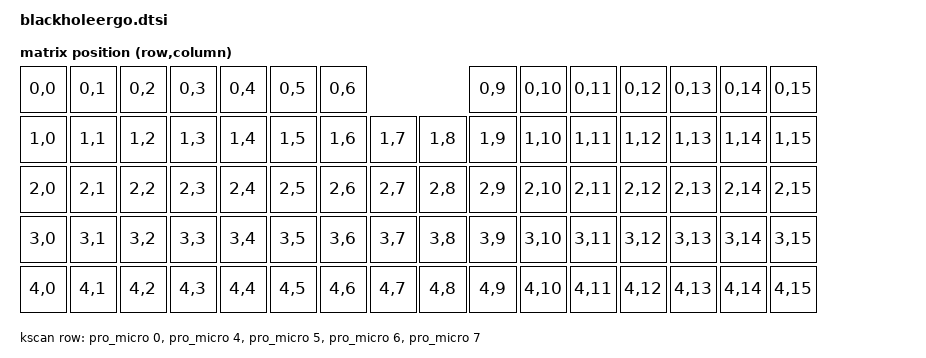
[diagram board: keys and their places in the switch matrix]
// This file was generated from a template. Edit it to match your keyboard.
// See https://zmk.dev/docs/development/hardware-integration/new-shield for more
// instructions.

#include <dt-bindings/zmk/matrix_transform.h>

#include "blackholeergo-layouts.dtsi"

/ {
    chosen {
        zmk,physical-layout = &default_layout;
        zephyr,display = &oled;
        
    };

    kscan: kscan {
        // If the hardware does not use a switch matrix, change this to the
        // appropriate driver and update the properties below to match.
        // See https://zmk.dev/docs/config/kscan for supported key scan drivers.
        compatible = "zmk,kscan-gpio-matrix";
        // Set this to "col2row" or "row2col" to match the hardware. If using
        // "row2col", change the col-gpios in the _left.overlay and _right.overlay
        // files to (GPIO_ACTIVE_HIGH | GPIO_PULL_DOWN) and the row-gpios here to
        // GPIO_ACTIVE_HIGH.
        diode-direction = "col2row";
        wakeup-source;

        // Replace these comments with the GPIO pins in the matrix.
        // See https://zmk.dev/docs/development/hardware-integration/new-shield#shield-overlays
        row-gpios
            = <&pro_micro 0 (GPIO_ACTIVE_HIGH | GPIO_PULL_DOWN)>
            , <&pro_micro 4 (GPIO_ACTIVE_HIGH | GPIO_PULL_DOWN)>
            , <&pro_micro 5 (GPIO_ACTIVE_HIGH | GPIO_PULL_DOWN)>
            , <&pro_micro 6 (GPIO_ACTIVE_HIGH | GPIO_PULL_DOWN)>
            , <&pro_micro 7 (GPIO_ACTIVE_HIGH | GPIO_PULL_DOWN)>
            ;
    };

    default_transform: default_transform {
        // See https://zmk.dev/docs/development/hardware-integration/new-shield#matrix-transform
        // for how to configure this
        compatible = "zmk,matrix-transform";
        columns = <16>;
        rows = <5>;

// | SW04 | SW10 | SW15 | SW20 | SW25 | SW29 | SW30 |             | SW30 | SW29 | SW25 | SW20 | SW15 | SW10 | SW04 |
// | SW03 | SW09 | SW14 | SW19 | SW24 | SW28 | SW34 | ES01   ES02 | SW34 | SW28 | SW24 | SW10 | SW14 | SW09 | SW03 |
// | SW02 | SW08 | SW13 | SW18 | SW23 | SW27 | SW35 | SW33 | SW33 | SW35 | SW27 | SW23 | SW18 | SW13 | SW08 | SW02 |
// | SW01 | SW07 | SW12 | SW17 | SW22 | SW26 |      |      |      |      | SW26 | SW22 | SW17 | SW12 | SW07 | SW01 |
// | SW06 | SW06 | SW11 | SW16 | SW21 |      |      | ---- | ---- |      |      | SW21 | SW16 | SW11 | SW06 | SW06 |
//                                    |      | SW38 |             | SW38 |      |
//                                    | SW36 | SW37 | SW32 | SW32 | SW37 | SW36 |
//                                                  | SW31 | SW31 |
        map = <
RC(0,0) RC(0,1) RC(0,2) RC(0,3) RC(0,4) RC(0,5) RC(0,6)                     RC(0,9) RC(0,10) RC(0,11)  RC(0,12) RC(0,13) RC(0,14) RC(0,15)
RC(1,0) RC(1,1) RC(1,2) RC(1,3) RC(1,4) RC(1,5) RC(1,6) RC(1,7)     RC(1,8) RC(1,9) RC(1,10) RC(1,11)  RC(1,12) RC(1,13) RC(1,14) RC(1,15)
RC(2,0) RC(2,1) RC(2,2) RC(2,3) RC(2,4) RC(2,5) RC(2,6) RC(2,7)     RC(2,8) RC(2,9) RC(2,10) RC(2,11)  RC(2,12) RC(2,13) RC(2,14) RC(2,15)
RC(3,0) RC(3,1) RC(3,2) RC(3,3) RC(3,4) RC(3,5) RC(3,6) RC(3,7)     RC(3,8) RC(3,9) RC(3,10) RC(3,11)  RC(3,12) RC(3,13) RC(3,14) RC(3,15)
RC(4,0) RC(4,1) RC(4,2) RC(4,3) RC(4,4) RC(4,5) RC(4,6) RC(4,7)     RC(4,8) RC(4,9) RC(4,10) RC(4,11)  RC(4,12) RC(4,13) RC(4,14) RC(4,15)
        >;
    };

    left_encoder: left_encoder {
        compatible = "alps,ec11";
        steps = <80>;
        status = "disabled";

        a-gpio = <&pro_micro 10 GPIO_PULL_UP>;
        b-gpio = <&pro_micro 16 GPIO_PULL_UP>;
    };

    right_encoder: right_encoder {
        compatible = "alps,ec11";
        steps = <80>;
        status = "disabled";

        a-gpio = <&pro_micro 16 GPIO_PULL_UP>;
        b-gpio = <&pro_micro 10 GPIO_PULL_UP>;        
    };

    &pro_micro_i2c {
        status = "okay";

        oled: ssd1306@3c {
            compatible = "solomon,ssd1306fb";
            reg = <0x3c>;
            width = <128>;
            height = <32>;
            segment-offset = <0>;
            page-offset = <0>:
            display-offset = <0>:
            multiplex-ratio = <31>;
            segment-remap;
            com-invdir;
            com-sequential;
            inversion-on;
            prechargep = <0x22>;
        }
    };
};
